# PIC32MZ1064DAK169 device description
Architecture: MIPS; Family: PIC32MZDA; Series: PIC32MZ
Registers are 32-bit, read-write, no defined reset value unless marked. A register's access mark holds for its fields unless they carry their own. Offsets are from the block's base; [hi:lo] are bit positions; {n}, {i} and the like mark numbered series; 'fields as' and 'values as' point back to an identical list.

## GPU
Instances: GPU 0x1f8eb000 in periph_indep
0x00 GPUBASEADDR

## HLVD
Instances: HLVD 0x1f801800 in periph_pb1_std
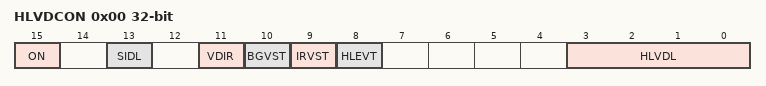
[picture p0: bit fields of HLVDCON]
0x00 HLVDCON — High/Low-Voltage Detect Control Register
  [15] ON — HLVD Module Enable bit
    1=HLVD module is enabled; 0=HLVD module is disabled
  [13] SIDL
  [11] VDIR — Voltage Change Direction Select bit
    1=Event occurs when voltage equals or exceeds the trip point (HLVDL); 0=Event occurs when voltage equals or falls below the trip point (HLVDL)
  [10] BGVST — Band Gap Reference Voltages Stable Status bit
    1=Indicates internal band gap voltage references is stable; 0=Indicates internal band gap voltage reference is not stable
  [9] IRVST
  [8] HLEVT — High/Low-Voltage Detection Event Status bit
    1=Indicates HLVD Event is active; 0=Indicates HLVD Event is not active
  [3:0] HLVDL — High/Low-Voltage Detection Limit Select bits(1)
    15=Selects analog input on HLVDIN; {v}=Selects trip point {v} (v=4..14); {v}=Reserved; do not use (v=0..3)

## ICAP
Instances: ICAP 0x1f842000 in periph_pb3_std
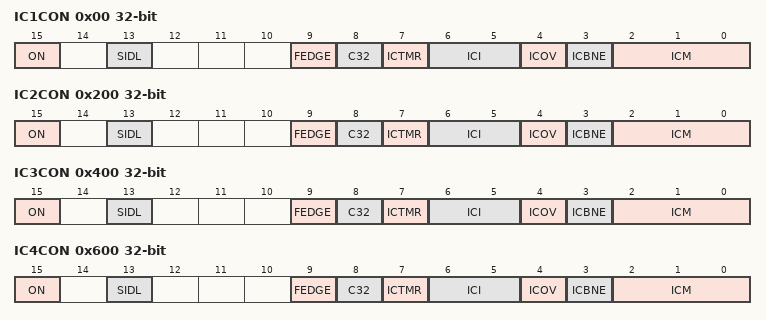
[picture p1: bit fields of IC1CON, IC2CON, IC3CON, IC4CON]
0x00 IC1CON — Input Capture x Control Register
  [15] ON — Input Capture Module Enable bit
    1=Module is enabled; 0=Disable and reset module
  [13] SIDL — Stop in Idle Control bit
    1=Halt in CPU Idle mode; 0=Continue to operate in CPU Idle mode
  [9] FEDGE — First Capture Edge Select bit
    1=Capture rising edge first; 0=Capture falling edge first
  [8] C32 — 32-bit Capture Select bit
    1=32-bit timer resource capture; 0=16-bit timer resource capture
  [7] ICTMR — Timer Select bit
    0=Timery is the counter source for capture; 1=Timerx is the counter source for capture
  [6:5] ICI — Interrupt Control bits
    3=Interrupt on every fourth capture event; 2=Interrupt on every third capture event; 1=Interrupt on every second capture event; 0=Interrupt on every capture event
  [4] ICOV — Input Capture Overflow Status Flag bit
    1=Input capture overflow is occurred; 0=No input capture overflow is occurred
  [3] ICBNE — Input Capture Buffer Not Empty Status bit
    1=Input capture buffer is not empty; at least one more capture value can be read; 0=Input capture buffer is empty
  [2:0] ICM — Input Capture Mode Select bits
    7=Interrupt-Only mode (only supported while in Sleep mode or Idle mode); 6=Simple Capture Event mode every edge; 5=Prescaled Capture Event mode every sixteenth rising edge; 4=Prescaled Capture Event mode every fourth rising edge; 3=Simple Capture Event mode every rising edge; 2=Simple Capture Event mode every falling edge; 1=Edge Detect mode every edge (rising and falling); 0=Input Capture module is disabled
0x10 IC1BUF ro
0x200 IC2CON — Input Capture x Control Register
  fields as IC1CON
0x210 IC2BUF ro
0x400 IC3CON — Input Capture x Control Register
  fields as IC1CON
0x410 IC3BUF ro
0x600 IC4CON — Input Capture x Control Register
  fields as IC1CON
0x610 IC4BUF ro
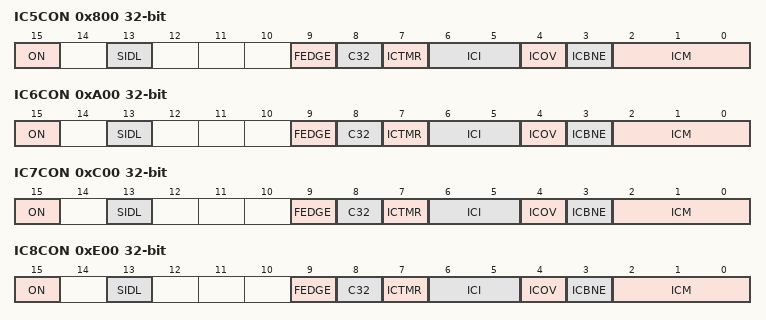
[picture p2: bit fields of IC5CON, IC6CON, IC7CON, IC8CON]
0x800 IC5CON — Input Capture x Control Register
  fields as IC1CON
0x810 IC5BUF ro
0xA00 IC6CON — Input Capture x Control Register
  fields as IC1CON
0xA10 IC6BUF ro
0xC00 IC7CON — Input Capture x Control Register
  fields as IC1CON
0xC10 IC7BUF ro
0xE00 IC8CON — Input Capture x Control Register
  fields as IC1CON
0xE10 IC8BUF ro
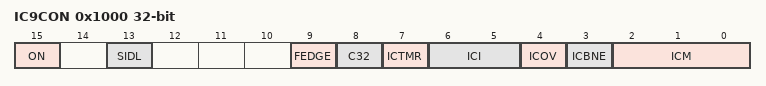
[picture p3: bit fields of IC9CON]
0x1000 IC9CON — Input Capture x Control Register
  fields as IC1CON
0x1010 IC9BUF ro

## JTAG
Instances: JTAG 0x1f801130 in periph_pb1_std
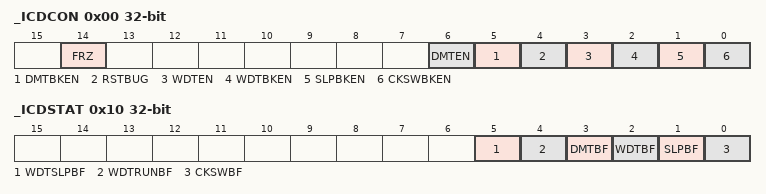
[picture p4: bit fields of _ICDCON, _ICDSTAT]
0x00 _ICDCON
  [14] FRZ, [6] DMTEN, [5] DMTBKEN, [4] RSTBUG, [3] WDTEN, [2] WDTBKEN, [1] SLPBKEN, [0] CKSWBKEN
0x10 _ICDSTAT
  [5] WDTSLPBF, [4] WDTRUNBF, [3] DMTBF, [2] WDTBF, [1] SLPBF, [0] CKSWBF

## OCMP
Instances: OCMP 0x1f844000 in periph_pb3_std
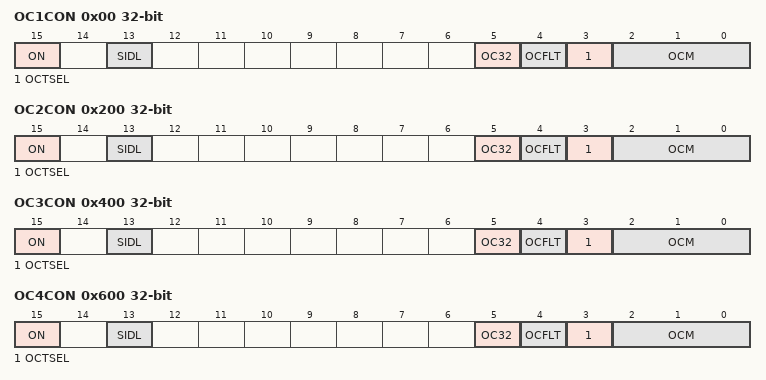
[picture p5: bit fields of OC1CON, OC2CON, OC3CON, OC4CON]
0x00 OC1CON — Output Compare 'x' Control Register
  [15] ON — Output Compare Peripheral On bit
    1=Output Compare peripheral is enabled; 0=Output Compare peripheral is disabled
  [13] SIDL — Stop in Idle Mode bit
    1=Discontinue operation when CPU enters Idle mode; 0=Continue operation in Idle mode
  [5] OC32 — 32-bit Compare Mode bit
    1=OCxR and/or OCxRS<31:0> are used for comparisions to the 32-bit timer source; 0=OCxR and OCxRS<15:0> are used for comparisons to the 16-bit timer source
  [4] OCFLT — PWM Fault Condition Status bit
    1=PWM Fault condition has occurred (cleared in HW only); 0=No PWM Fault condition has occurred
  [3] OCTSEL — Output Compare Timer Select bit
    1=Timery is the clock source for this Output Compare module; 0=Timerx is the clock source for this Output Compare module
  [2:0] OCM — Output Compare Mode Select bits
    7=PWM mode on OCx; Fault pin enabled; 6=PWM mode on OCx; Fault pin diabled; 5=Initialize OCx pin low; generate continious output pulses on OCx pin; 4=Initialize OCx pin low; generate single output pulse on OCx pin; 3=Compare event toggles OCx pin; 2=Initialize OCx pin high; compare event forces OCx pin low; 1=Initialize OCx pin low; compare event forces OCx pin high; 0=Output compare peripheral is disabled but continues to draw current
0x10 OC1R
0x20 OC1RS
0x200 OC2CON — Output Compare 'x' Control Register
  fields as OC1CON
0x210 OC2R
0x220 OC2RS
0x400 OC3CON — Output Compare 'x' Control Register
  fields as OC1CON
0x410 OC3R
0x420 OC3RS
0x600 OC4CON — Output Compare 'x' Control Register
  fields as OC1CON
0x610 OC4R
0x620 OC4RS
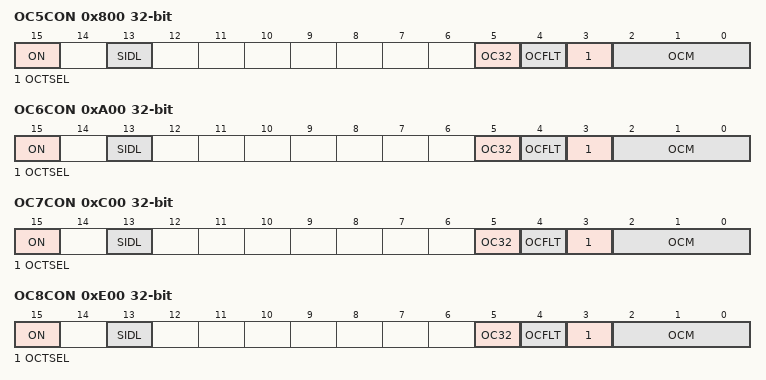
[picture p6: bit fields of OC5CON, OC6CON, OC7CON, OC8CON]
0x800 OC5CON — Output Compare 'x' Control Register
  fields as OC1CON
0x810 OC5R
0x820 OC5RS
0xA00 OC6CON — Output Compare 'x' Control Register
  fields as OC1CON
0xA10 OC6R
0xA20 OC6RS
0xC00 OC7CON — Output Compare 'x' Control Register
  fields as OC1CON
0xC10 OC7R
0xC20 OC7RS
0xE00 OC8CON — Output Compare 'x' Control Register
  fields as OC1CON
0xE10 OC8R
0xE20 OC8RS
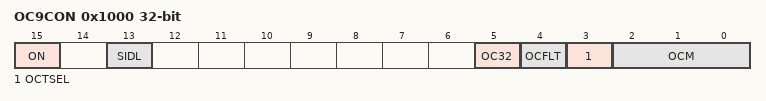
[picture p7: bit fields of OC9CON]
0x1000 OC9CON — Output Compare 'x' Control Register
  fields as OC1CON
0x1010 OC9R
0x1020 OC9RS

## Notices in the file
Copyright (c) 2017 Microchip Technology Inc.
SPDX-License-Identifier: Apache-2.0
Licensed under the Apache License, Version 2.0 (the "License");
you may not use this file except in compliance with the License.
You may obtain a copy of the License at
http://www.apache.org/licenses/LICENSE-2.0
Unless required by applicable law or agreed to in writing, software
distributed under the License is distributed on an "AS IS" BASIS,
WITHOUT WARRANTIES OR CONDITIONS OF ANY KIND, either express or implied.
See the License for the specific language governing permissions and
limitations under the License.
